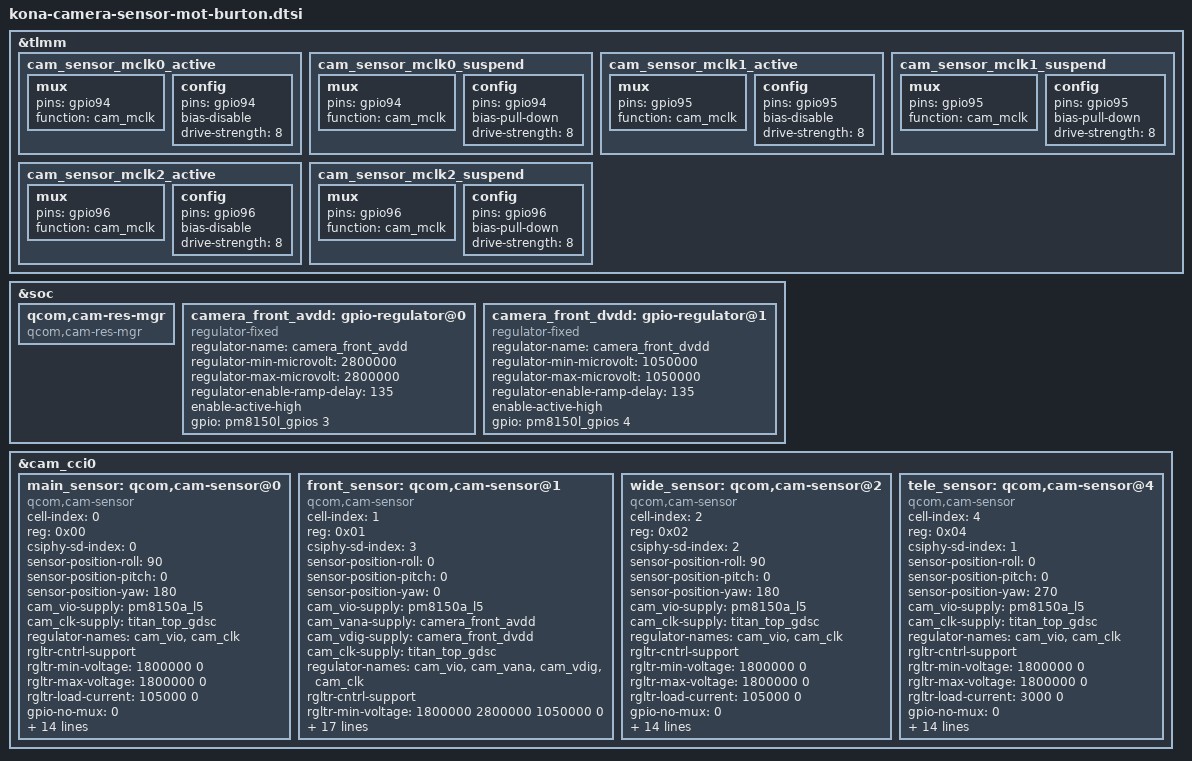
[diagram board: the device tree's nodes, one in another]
#include <dt-bindings/clock/qcom,camcc-kona.h>

&tlmm {
	cam_sensor_mclk0_active: cam_sensor_mclk0_active {
		/* MCLK0 */
		mux {
			pins = "gpio94";
			function = "cam_mclk";
		};

		config {
			pins = "gpio94";
			bias-disable; /* No PULL */
			drive-strength = <8>; /* 8 MA */
		};
	};

	cam_sensor_mclk0_suspend: cam_sensor_mclk0_suspend {
		/* MCLK0 */
		mux {
			pins = "gpio94";
			function = "cam_mclk";
		};

		config {
			pins = "gpio94";
			bias-pull-down; /* PULL DOWN */
			drive-strength = <8>; /* 8 MA */
		};
	};

	cam_sensor_mclk1_active: cam_sensor_mclk1_active {
		/* MCLK1 */
		mux {
			pins = "gpio95";
			function = "cam_mclk";
		};

		config {
			pins = "gpio95";
			bias-disable; /* No PULL */
			drive-strength = <8>; /* 2 MA */
		};
	};

    cam_sensor_mclk1_suspend: cam_sensor_mclk1_suspend {
		/* MCLK1 */
		mux {
			pins = "gpio95";
			function = "cam_mclk";
		};

		config {
			pins = "gpio95";
			bias-pull-down; /* PULL DOWN */
			drive-strength = <8>; /* 2 MA */
		};
	};

	cam_sensor_mclk2_active: cam_sensor_mclk2_active {
		/* MCLK2 */
		mux {
			pins = "gpio96";
			function = "cam_mclk";
		};

		config {
			pins = "gpio96";
			bias-disable; /* No PULL */
			drive-strength = <8>; /* 8 MA */
		};
	};

	cam_sensor_mclk2_suspend: cam_sensor_mclk2_suspend {
		/* MCLK2 */
		mux {
			pins = "gpio96";
			function = "cam_mclk";
		};

		config {
			pins = "gpio96";
			bias-pull-down; /* PULL DOWN */
			drive-strength = <8>; /* 8 MA */
		};
	};

};

&soc {
	qcom,cam-res-mgr {
		compatible = "qcom,cam-res-mgr";
		status = "ok";
	};

	camera_front_avdd: gpio-regulator@0{
		compatible = "regulator-fixed";
		regulator-name = "camera_front_avdd";
		regulator-min-microvolt = <2800000>;
		regulator-max-microvolt = <2800000>;
		regulator-enable-ramp-delay = <135>;
		enable-active-high;
		gpio = <&pm8150l_gpios 3 0>;
	};

	camera_front_dvdd: gpio-regulator@1{
		compatible = "regulator-fixed";
		regulator-name = "camera_front_dvdd";
		regulator-min-microvolt = <1050000>;
		regulator-max-microvolt = <1050000>;
		regulator-enable-ramp-delay = <135>;
		enable-active-high;
		gpio = <&pm8150l_gpios 4 0>;
	};
};

&cam_cci0 {
	main_sensor: qcom,cam-sensor@0 {
		cell-index = <0>;
		compatible = "qcom,cam-sensor";
		reg = <0x00>;
		csiphy-sd-index = <0>;
		sensor-position-roll = <90>;
		sensor-position-pitch = <0>;
		sensor-position-yaw = <180>;
		cam_vio-supply = <&pm8150a_l5>;
		cam_clk-supply = <&titan_top_gdsc>;
		regulator-names = "cam_vio", "cam_clk";
		rgltr-cntrl-support;
		rgltr-min-voltage = <1800000 0>;
		rgltr-max-voltage = <1800000 0>;
		rgltr-load-current = <105000 0>;
		gpio-no-mux = <0>;
		pinctrl-names = "cam_default", "cam_suspend";
		pinctrl-0 = <&cam_sensor_mclk0_active
				&cam_sensor_active_rear>;
		pinctrl-1 = <&cam_sensor_mclk0_suspend
				&cam_sensor_suspend_rear>;
		gpios = <&tlmm 94 0>,
			<&tlmm 93 0>;
		gpio-reset = <1>;
		gpio-req-tbl-num = <0 1>;
		gpio-req-tbl-flags = <1 0>;
		gpio-req-tbl-label = "CAMIF_MCLK0",
				"CAM_RESET0";
		sensor-mode = <0>;
		cci-master = <0>;
		status = "ok";
		clocks = <&clock_camcc CAM_CC_MCLK0_CLK>;
		clock-names = "cam_clk";
		clock-cntl-level = "turbo";
		clock-rates = <24000000>;
	};

	front_sensor: qcom,cam-sensor@1 {
		cell-index = <1>;
		compatible = "qcom,cam-sensor";
		reg = <0x01>;
		csiphy-sd-index = <3>;
		sensor-position-roll = <0>;
		sensor-position-pitch = <0>;
		sensor-position-yaw = <0>;
		cam_vio-supply = <&pm8150a_l5>;
		cam_vana-supply = <&camera_front_avdd>;
		cam_vdig-supply = <&camera_front_dvdd>;
		cam_clk-supply = <&titan_top_gdsc>;
		regulator-names = "cam_vio", "cam_vana", "cam_vdig",
			"cam_clk";
		rgltr-cntrl-support;
		rgltr-min-voltage = <1800000 2800000 1050000 0>;
		rgltr-max-voltage = <1800000 2800000 1050000 0>;
		rgltr-load-current = <19800 390000 53000 0>;
		gpio-no-mux = <0>;
		pinctrl-names = "cam_default", "cam_suspend";
		pinctrl-0 = <&cam_sensor_mclk3_active
					&cam_sensor_active_3>;
		pinctrl-1 = <&cam_sensor_mclk3_suspend
					&cam_sensor_suspend_3>;
		gpios = <&tlmm 97 0>,
			<&tlmm 109 0>;
		gpio-reset = <1>;
		gpio-req-tbl-num = <0 1>;
		gpio-req-tbl-flags = <1 0>;
		gpio-req-tbl-label = "CAMIF_MCLK3",
				     "CAM_RESET3";
		sensor-mode = <0>;
		cci-master = <1>;
		status = "ok";
		clocks = <&clock_camcc CAM_CC_MCLK3_CLK>;
		clock-names = "cam_clk";
		clock-cntl-level = "turbo";
		clock-rates = <24000000>;
	};

	wide_sensor: qcom,cam-sensor@2 {
		cell-index = <2>;
		compatible = "qcom,cam-sensor";
		reg = <0x02>;
		csiphy-sd-index = <2>;
		sensor-position-roll = <90>;
		sensor-position-pitch = <0>;
		sensor-position-yaw = <180>;
		cam_vio-supply = <&pm8150a_l5>;
		cam_clk-supply = <&titan_top_gdsc>;
		regulator-names = "cam_vio", "cam_clk";
		rgltr-cntrl-support;
		rgltr-min-voltage = <1800000 0>;
		rgltr-max-voltage = <1800000 0>;
		rgltr-load-current = <105000 0>;
		gpio-no-mux = <0>;
		pinctrl-names = "cam_default", "cam_suspend";
		pinctrl-0 = <&cam_sensor_mclk2_active
				&cam_sensor_active_rst2>;
		pinctrl-1 = <&cam_sensor_mclk2_suspend
				&cam_sensor_suspend_rst2>;
		gpios = <&tlmm 96 0>,
			<&tlmm 78 0>;
		gpio-reset = <1>;
		gpio-req-tbl-num = <0 1>;
		gpio-req-tbl-flags = <1 0>;
		gpio-req-tbl-label = "CAMIF_MCLK2",
				"CAM_RESET2";
		sensor-mode = <0>;
		cci-master = <0>;
		status = "ok";
		clocks = <&clock_camcc CAM_CC_MCLK2_CLK>;
		clock-names = "cam_clk";
		clock-cntl-level = "turbo";
		clock-rates = <24000000>;
	};

	tele_sensor: qcom,cam-sensor@4 {
		cell-index = <4>;
		reg = <0x04>;
		compatible = "qcom,cam-sensor";
		csiphy-sd-index = <1>;
		sensor-position-roll = <0>;
		sensor-position-pitch = <0>;
		sensor-position-yaw = <270>;
		cam_vio-supply = <&pm8150a_l5>;
		cam_clk-supply = <&titan_top_gdsc>;
		regulator-names = "cam_vio", "cam_clk";
		rgltr-cntrl-support;
		rgltr-min-voltage = <1800000 0>;
		rgltr-max-voltage = <1800000 0>;
		rgltr-load-current = <3000 0>;
		gpio-no-mux = <0>;
		pinctrl-names = "cam_default", "cam_suspend";
		pinctrl-0 = <&cam_sensor_mclk1_active
				     &cam_sensor_active_rear_aux>;
		pinctrl-1 = <&cam_sensor_mclk1_suspend
				     &cam_sensor_suspend_rear_aux>;
		gpios = <&tlmm 95 0>,
			<&tlmm 92 0>;
		gpio-reset = <1>;
		gpio-req-tbl-num = <0 1 >;
		gpio-req-tbl-flags = <1 0 >;
		gpio-req-tbl-label =    "CAMIF_MCLK1",
					"CAM_RESET1";
		sensor-mode = <0>;
		cci-master = <1>;
		status = "ok";
		clocks = <&clock_camcc CAM_CC_MCLK1_CLK>;
		clock-names = "cam_clk";
		clock-cntl-level = "turbo";
		clock-rates = <24000000>;
	};
};
